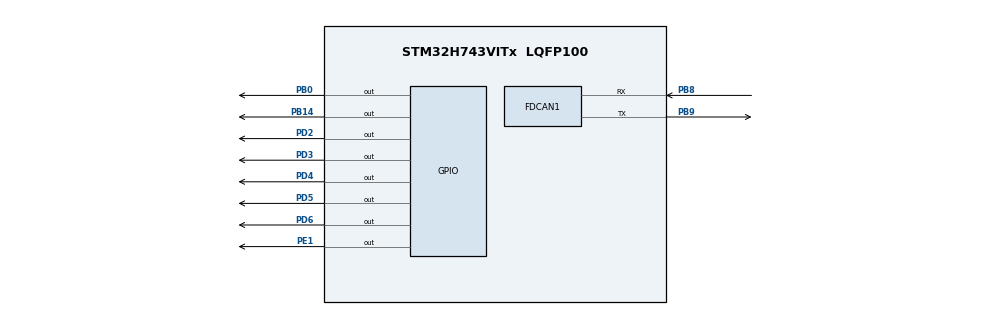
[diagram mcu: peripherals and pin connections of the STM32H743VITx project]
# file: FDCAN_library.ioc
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FDCAN1.ClockCalibrationCCU=DISABLE
FDCAN1.DataPrescaler=25
FDCAN1.DataTimeSeg1=2
FDCAN1.FrameFormat=FDCAN_FRAME_FD_NO_BRS
FDCAN1.NominalSyncJumpWidth=13
FDCAN1.NominalTimeSeg1=86
FDCAN1.NominalTimeSeg2=13
FDCAN1.RxFifo0ElmtsNbr=1
FDCAN1.TxElmtSize=FDCAN_DATA_BYTES_8
FDCAN1.TxFifoQueueElmtsNbr=1
Mcu.Family=STM32H7
Mcu.Name=STM32H743VITx
Mcu.Package=LQFP100
NVIC.FDCAN1_IT0_IRQn=true\:15\:0\:true\:true\:true\:1\:true\:true\:true
NVIC.PriorityGroup=NVIC_PRIORITYGROUP_4
PA13\ (JTMS/SWDIO).Mode=Serial_Wire
PA13\ (JTMS/SWDIO).Signal=DEBUG_JTMS-SWDIO
PA14\ (JTCK/SWCLK).Mode=Serial_Wire
PA14\ (JTCK/SWCLK).Signal=DEBUG_JTCK-SWCLK
PB0.Signal=GPIO_Output
PB14.Signal=GPIO_Output
PB8.Mode=FDCAN_Activate
PB8.Signal=FDCAN1_RX
PB9.Mode=FDCAN_Activate
PB9.Signal=FDCAN1_TX
PD2.Signal=GPIO_Output
PD3.Signal=GPIO_Output
PD4.Signal=GPIO_Output
PD5.Signal=GPIO_Output
PD6.Signal=GPIO_Output
PE1.Signal=GPIO_Output
PH0-OSC_IN\ (PH0).Mode=HSE-External-Oscillator
PH0-OSC_IN\ (PH0).Signal=RCC_OSC_IN
PH1-OSC_OUT\ (PH1).Mode=HSE-External-Oscillator
PH1-OSC_OUT\ (PH1).Signal=RCC_OSC_OUT
ProjectManager.HeapSize=0x200
ProjectManager.StackSize=0x400
ProjectManager.TargetToolchain=STM32CubeIDE
RCC.ADCFreq_Value=250000000
RCC.APB1Freq_Value=120000000
RCC.APB2Freq_Value=120000000
RCC.APB3Freq_Value=120000000
RCC.APB4Freq_Value=120000000
RCC.CortexFreq_Value=480000000
RCC.D1PPRE=RCC_APB3_DIV2
RCC.D2PPRE1=RCC_APB1_DIV2
RCC.D2PPRE2=RCC_APB2_DIV2
RCC.D3PPRE=RCC_APB4_DIV2
RCC.DIVM1=1
RCC.DIVM2=2
RCC.DIVN1=120
RCC.DIVN2=125
RCC.DIVQ1=4
RCC.DIVQ2=4
RCC.DIVR1=8
RCC.FDCANCLockSelection=RCC_FDCANCLKSOURCE_PLL2
RCC.HCLKFreq_Value=240000000
RCC.HPRE=RCC_HCLK_DIV2
RCC.HSE_VALUE=8000000
RCC.PLL2FRACN=0
RCC.PLL3FRACN=0
RCC.PLLFRACN=0
RCC.PLLSourceVirtual=RCC_PLLSOURCE_HSE
RCC.SYSCLKFreq_VALUE=480000000
RCC.SYSCLKSource=RCC_SYSCLKSOURCE_PLLCLK
RCC.USBFreq_Value=240000000
board=custom

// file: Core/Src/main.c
/* USER CODE BEGIN Header */
/**
 ******************************************************************************
 * @file           : main.c
 * @brief          : Main program body
 ******************************************************************************
 * @attention
 *
 * Copyright (c) 2023 STMicroelectronics.
 * All rights reserved.
 *
 * This software is licensed under terms that can be found in the LICENSE file
 * in the root directory of this software component.
 * If no LICENSE file comes with this software, it is provided AS-IS.
 *
 ******************************************************************************
 */
/* USER CODE END Header */
#include <FDCAN.h>
#include "main.h"

FDCAN_HandleTypeDef hfdcan1;

/* USER CODE BEGIN PV */
extern uint64_t buffer_time[32];

int64_t INTEIRO_Tx = 0;
float FLOAT_Tx = 0;
uint8_t Precisao_FLOAT = 0;
double DOUBLE_Tx = 0;
uint8_t Precisao_DOUBLE = 0;

/* USER CODE END PV */

void SystemClock_Config(void);
static void MX_GPIO_Init(void);
static void MX_FDCAN1_Init(void);
static void MX_NVIC_Init(void);

/* USER CODE BEGIN 0 */
// FDCAN1 Defines
/* USER CODE END 0 */

int main(void) {

	/* MCU Configuration--------------------------------------------------------*/

	/* Reset of all peripherals, Initializes the Flash interface and the Systick. */
	HAL_Init();

	/* Configure the system clock */
	SystemClock_Config();

	/* Initialize all configured peripherals */
	MX_GPIO_Init();
	MX_FDCAN1_Init();

	/* Initialize interrupts */
	MX_NVIC_Init();
	/* USER CODE BEGIN 2 */
	CAN_Init();

	/* USER CODE END 2 */

	/* Infinite loop */
	while (1) {

		/* USER CODE BEGIN 3 */
		HAL_GPIO_TogglePin(GPIOD, GPIO_PIN_6);
	}
	/* USER CODE END 3 */
}

void SystemClock_Config(void) {
	RCC_OscInitTypeDef RCC_OscInitStruct = { 0 };
	RCC_ClkInitTypeDef RCC_ClkInitStruct = { 0 };

	/** Supply configuration update enable
	 */
	HAL_PWREx_ConfigSupply(PWR_LDO_SUPPLY);

	/** Configure the main internal regulator output voltage
	 */
	__HAL_PWR_VOLTAGESCALING_CONFIG(PWR_REGULATOR_VOLTAGE_SCALE0);

	while (!__HAL_PWR_GET_FLAG(PWR_FLAG_VOSRDY)) {
	}

	/** Macro to configure the PLL clock source
	 */
	__HAL_RCC_PLL_PLLSOURCE_CONFIG(RCC_PLLSOURCE_HSE);

	/** Initializes the RCC Oscillators according to the specified parameters
	 * in the RCC_OscInitTypeDef structure.
	 */
	RCC_OscInitStruct.OscillatorType = RCC_OSCILLATORTYPE_HSE;
	RCC_OscInitStruct.HSEState = RCC_HSE_ON;
	RCC_OscInitStruct.PLL.PLLState = RCC_PLL_ON;
	RCC_OscInitStruct.PLL.PLLSource = RCC_PLLSOURCE_HSE;
	RCC_OscInitStruct.PLL.PLLM = 1;
	RCC_OscInitStruct.PLL.PLLN = 120;
	RCC_OscInitStruct.PLL.PLLP = 2;
	RCC_OscInitStruct.PLL.PLLQ = 4;
	RCC_OscInitStruct.PLL.PLLR = 8;
	RCC_OscInitStruct.PLL.PLLRGE = RCC_PLL1VCIRANGE_3;
	RCC_OscInitStruct.PLL.PLLVCOSEL = RCC_PLL1VCOWIDE;
	RCC_OscInitStruct.PLL.PLLFRACN = 0;
	if (HAL_RCC_OscConfig(&RCC_OscInitStruct) != HAL_OK) {
		Error_Handler();
	}

	/** Initializes the CPU, AHB and APB buses clocks
	 */
	RCC_ClkInitStruct.ClockType = RCC_CLOCKTYPE_HCLK | RCC_CLOCKTYPE_SYSCLK
			| RCC_CLOCKTYPE_PCLK1 | RCC_CLOCKTYPE_PCLK2 | RCC_CLOCKTYPE_D3PCLK1
			| RCC_CLOCKTYPE_D1PCLK1;
	RCC_ClkInitStruct.SYSCLKSource = RCC_SYSCLKSOURCE_PLLCLK;
	RCC_ClkInitStruct.SYSCLKDivider = RCC_SYSCLK_DIV1;
	RCC_ClkInitStruct.AHBCLKDivider = RCC_HCLK_DIV2;
	RCC_ClkInitStruct.APB3CLKDivider = RCC_APB3_DIV2;
	RCC_ClkInitStruct.APB1CLKDivider = RCC_APB1_DIV2;
	RCC_ClkInitStruct.APB2CLKDivider = RCC_APB2_DIV2;
	RCC_ClkInitStruct.APB4CLKDivider = RCC_APB4_DIV2;

	if (HAL_RCC_ClockConfig(&RCC_ClkInitStruct, FLASH_LATENCY_4) != HAL_OK) {
		Error_Handler();
	}
}

/**
 * @brief NVIC Configuration.
 * @retval None
 */
static void MX_NVIC_Init(void) {
	/* FDCAN1_IT0_IRQn interrupt configuration */
	HAL_NVIC_SetPriority(FDCAN1_IT0_IRQn, 15, 0);
	HAL_NVIC_EnableIRQ(FDCAN1_IT0_IRQn);
}

static void MX_FDCAN1_Init(void) {

	hfdcan1.Instance = FDCAN1;
	hfdcan1.Init.FrameFormat = FDCAN_FRAME_FD_NO_BRS;
	hfdcan1.Init.Mode = FDCAN_MODE_NORMAL;
	hfdcan1.Init.AutoRetransmission = DISABLE;
	hfdcan1.Init.TransmitPause = DISABLE;
	hfdcan1.Init.ProtocolException = DISABLE;
	hfdcan1.Init.NominalPrescaler = 1;
	hfdcan1.Init.NominalSyncJumpWidth = 13;
	hfdcan1.Init.NominalTimeSeg1 = 86;
	hfdcan1.Init.NominalTimeSeg2 = 13;
	hfdcan1.Init.DataPrescaler = 25;
	hfdcan1.Init.DataSyncJumpWidth = 1;
	hfdcan1.Init.DataTimeSeg1 = 2;
	hfdcan1.Init.DataTimeSeg2 = 1;
	hfdcan1.Init.MessageRAMOffset = 0;
	hfdcan1.Init.StdFiltersNbr = 0;
	hfdcan1.Init.ExtFiltersNbr = 0;
	hfdcan1.Init.RxFifo0ElmtsNbr = 1;
	hfdcan1.Init.RxFifo0ElmtSize = FDCAN_DATA_BYTES_8;
	hfdcan1.Init.RxFifo1ElmtsNbr = 0;
	hfdcan1.Init.RxFifo1ElmtSize = FDCAN_DATA_BYTES_8;
	hfdcan1.Init.RxBuffersNbr = 0;
	hfdcan1.Init.RxBufferSize = FDCAN_DATA_BYTES_8;
	hfdcan1.Init.TxEventsNbr = 0;
	hfdcan1.Init.TxBuffersNbr = 0;
	hfdcan1.Init.TxFifoQueueElmtsNbr = 1;
	hfdcan1.Init.TxFifoQueueMode = FDCAN_TX_FIFO_OPERATION;
	hfdcan1.Init.TxElmtSize = FDCAN_DATA_BYTES_8;
	if (HAL_FDCAN_Init(&hfdcan1) != HAL_OK) {
		Error_Handler();
	}

}

static void MX_GPIO_Init(void) {
	GPIO_InitTypeDef GPIO_InitStruct = { 0 };

	/* GPIO Ports Clock Enable */
	__HAL_RCC_GPIOH_CLK_ENABLE();
	__HAL_RCC_GPIOB_CLK_ENABLE();
	__HAL_RCC_GPIOA_CLK_ENABLE();
	__HAL_RCC_GPIOD_CLK_ENABLE();
	__HAL_RCC_GPIOE_CLK_ENABLE();

	/*Configure GPIO pin Output Level */
	HAL_GPIO_WritePin(GPIOB, GPIO_PIN_0 | GPIO_PIN_14, GPIO_PIN_RESET);

	/*Configure GPIO pin Output Level */
	HAL_GPIO_WritePin(GPIOD,
			GPIO_PIN_2 | GPIO_PIN_3 | GPIO_PIN_4 | GPIO_PIN_5 | GPIO_PIN_6,
			GPIO_PIN_RESET);

	/*Configure GPIO pin Output Level */
	HAL_GPIO_WritePin(GPIOE, GPIO_PIN_1, GPIO_PIN_RESET);

	/*Configure GPIO pins : PB0 PB14 */
	GPIO_InitStruct.Pin = GPIO_PIN_0 | GPIO_PIN_14;
	GPIO_InitStruct.Mode = GPIO_MODE_OUTPUT_PP;
	GPIO_InitStruct.Pull = GPIO_NOPULL;
	GPIO_InitStruct.Speed = GPIO_SPEED_FREQ_LOW;
	HAL_GPIO_Init(GPIOB, &GPIO_InitStruct);

	/*Configure GPIO pins : PD2 PD3 PD4 PD5
	 PD6 */
	GPIO_InitStruct.Pin = GPIO_PIN_2 | GPIO_PIN_3 | GPIO_PIN_4 | GPIO_PIN_5
			| GPIO_PIN_6;
	GPIO_InitStruct.Mode = GPIO_MODE_OUTPUT_PP;
	GPIO_InitStruct.Pull = GPIO_NOPULL;
	GPIO_InitStruct.Speed = GPIO_SPEED_FREQ_LOW;
	HAL_GPIO_Init(GPIOD, &GPIO_InitStruct);

	/*Configure GPIO pin : PE1 */
	GPIO_InitStruct.Pin = GPIO_PIN_1;
	GPIO_InitStruct.Mode = GPIO_MODE_OUTPUT_PP;
	GPIO_InitStruct.Pull = GPIO_NOPULL;
	GPIO_InitStruct.Speed = GPIO_SPEED_FREQ_LOW;
	HAL_GPIO_Init(GPIOE, &GPIO_InitStruct);

}

void Error_Handler(void) {
	/* USER CODE BEGIN Error_Handler_Debug */
	/* User can add his own implementation to report the HAL error return state */
	__disable_irq();
	while (1) {
		HAL_GPIO_TogglePin(GPIOB, GPIO_PIN_14);
	}
	/* USER CODE END Error_Handler_Debug */
}
